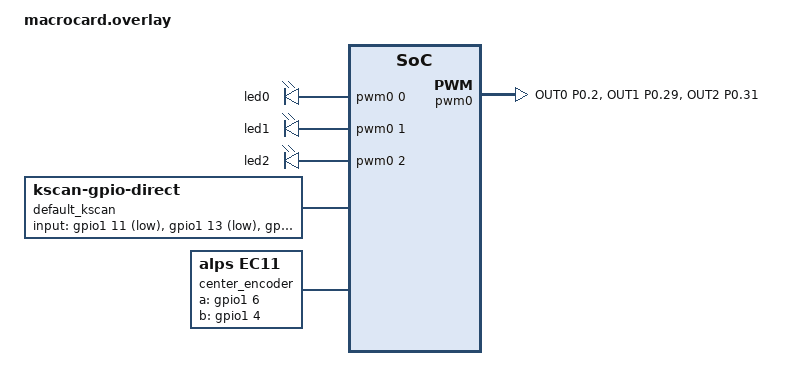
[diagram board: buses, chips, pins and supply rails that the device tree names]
/ {
    chosen {
        zmk,kscan = &default_kscan;
    };

    aliases {
        led-red = &led0;
        led-green = &led1;
        led-blue = &led2;
    };

    pwmleds: pwmleds {
        compatible = "pwm-leds";
        
        led0: led_0 {
            pwms = <&pwm0 0 PWM_MSEC(20) PWM_POLARITY_NORMAL>;
        };
        
        led1: led_1 {
            pwms = <&pwm0 1 PWM_MSEC(20) PWM_POLARITY_NORMAL>;
        };
        
        led2: led_2 {
            pwms = <&pwm0 2 PWM_MSEC(20) PWM_POLARITY_NORMAL>;
        };
    };

    default_kscan: kscan {
        compatible = "zmk,kscan-gpio-direct";
        wakeup-source;
        
        input-gpios = 
            <&gpio1 11  (GPIO_ACTIVE_LOW | GPIO_PULL_UP)>,   // Switch 1 on P1.11
            <&gpio1 13  (GPIO_ACTIVE_LOW | GPIO_PULL_UP)>,   // Switch 2 on P1.13
            <&gpio1 15  (GPIO_ACTIVE_LOW | GPIO_PULL_UP)>,   // Switch 3 on P1.15
            <&gpio0 11  (GPIO_ACTIVE_LOW | GPIO_PULL_UP)>,   // Encoder switch
            //Add encoder pins to input-gpios to enable them as wakeup sources
            <&gpio1 6   (GPIO_ACTIVE_LOW | GPIO_PULL_UP)>,   
            <&gpio1 4   (GPIO_ACTIVE_LOW | GPIO_PULL_UP)>;
    };

    center_encoder: encoder_center {
        compatible = "alps,ec11";
        // Swap pins to invert rotation
        a-gpios = <&gpio1 6 (GPIO_ACTIVE_HIGH | GPIO_PULL_UP)>;  // Pin A on P1.04
        b-gpios = <&gpio1 4 (GPIO_ACTIVE_HIGH | GPIO_PULL_UP)>;  // Pin B on P1.06
        steps = <80>;
        status = "okay";
    };
    sensors: sensors {
        compatible = "zmk,keymap-sensors";
        sensors = <&center_encoder>;
    };
};

&pinctrl {
    pwm0_default: pwm0_default {
        group1 {
            psels = <NRF_PSEL(PWM_OUT0, 0, 2)>,     // Red LED on P0.02
                    <NRF_PSEL(PWM_OUT1, 0, 29)>,    // Green LED on P0.29
                    <NRF_PSEL(PWM_OUT2, 0, 31)>;    // Blue LED on P0.31
        };
    };
};

&pwm0 {
    status = "okay";
    pinctrl-0 = <&pwm0_default>;
    pinctrl-names = "default";
};

&center_encoder {
    status = "okay";
};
